# fan register map
Vendor: Texas Instruments
Peripheral module from a debugger description file (folder sc4e129bnczad).
Registers are 32-bit, read-write, no defined reset value unless marked. A register's access mark holds for its fields unless they carry their own. Offsets are as the file gives them; lines under a group give offsets from that group; [hi:lo] are bit positions; {n}, {i} and the like mark numbered series; 'fields as' and 'values as' point back to an identical list; <NAME> marks a mode.

## FAN0 — Fan Control register offsets
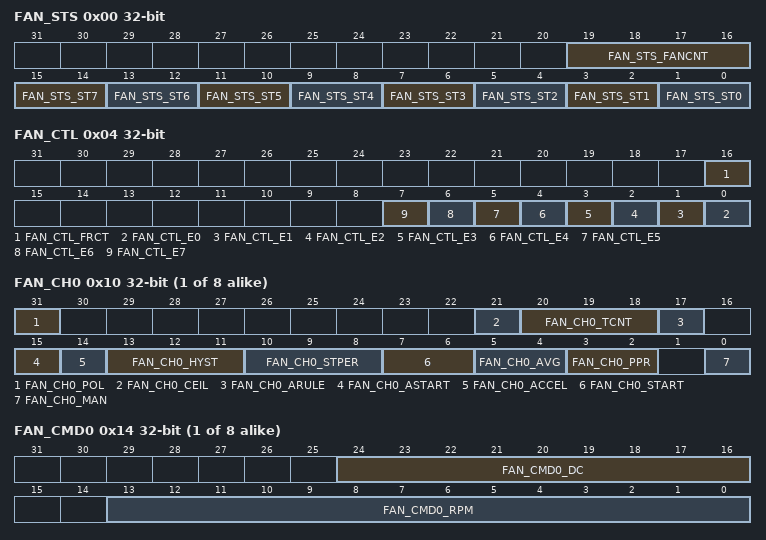
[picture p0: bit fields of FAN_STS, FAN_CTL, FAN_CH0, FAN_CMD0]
0x00 FAN_STS ro — FAN Status
  [19:16] FAN_STS_FANCNT — Fan Count
  [2n+1:2n] FAN_STS_ST{n} (n=0..7) — Fan {n} Status
    0=FAN_STS_ST{n}_STALLED (Stalled); 1=FAN_STS_ST{n}_CHANGING (Changing); 2=FAN_STS_ST{n}_LOCKED (Locked); 3=FAN_STS_ST{n}_NOATTAIN (No Attain)
0x04 FAN_CTL — FAN Control
  [16] FAN_CTL_FRCT — Fractional Output
  [n] FAN_CTL_E{n} (n=0..7) — Fan {n} Enable
{0x10+0x10*i} FAN_CH{i} (i=0..7) — FAN Channel {i} Setup
  [31] FAN_CH{i}_POL — PWM Polarity Mode
  [21] FAN_CH{i}_CEIL — Ceiling Mode
  [20:18] FAN_CH{i}_TCNT — Tachometer Count
  [17] FAN_CH{i}_ARULE — Adjustment Rule
  [15] FAN_CH{i}_ASTART — Auto Restart
  [14] FAN_CH{i}_ACCEL — Acceleration and Deceleration Rule
  [13:11] FAN_CH{i}_HYST — Hysteresis Adjustment on PID Adjust
  [10:8] FAN_CH{i}_STPER — Start Period
  [7:6] FAN_CH{i}_START — Fast Start Rule
    0=FAN_CH{i}_START_NOFAST (No fast start); 1=FAN_CH{i}_START_50DC (50% duty cycle); 2=FAN_CH{i}_START_75DC (75% duty cycle); 3=FAN_CH{i}_START_100DC (100% duty cycle)
  [5:4] FAN_CH{i}_AVG — Averaging of Tachometer
    0=No averaging; 1=Average 2 edges; 2=Average 4 edges; 3=Average 8 edges
  [3:2] FAN_CH{i}_PPR — Pulse per Revolution on Tachometer
    0=1 pulse per revolution; 1=2 pulses per revolution; 2=4 pulses per revolution; 3=8 pulses per revolution
  [0] FAN_CH{i}_MAN — Control Type
{0x14+0x10*i} FAN_CMD{i} (i=0..7) — FAN Channel {i} Command
  [24:16] FAN_CMD{i}_DC — PWM Duty Cycle
  [13:0] FAN_CMD{i}_RPM — Fan Speed (in RPM)
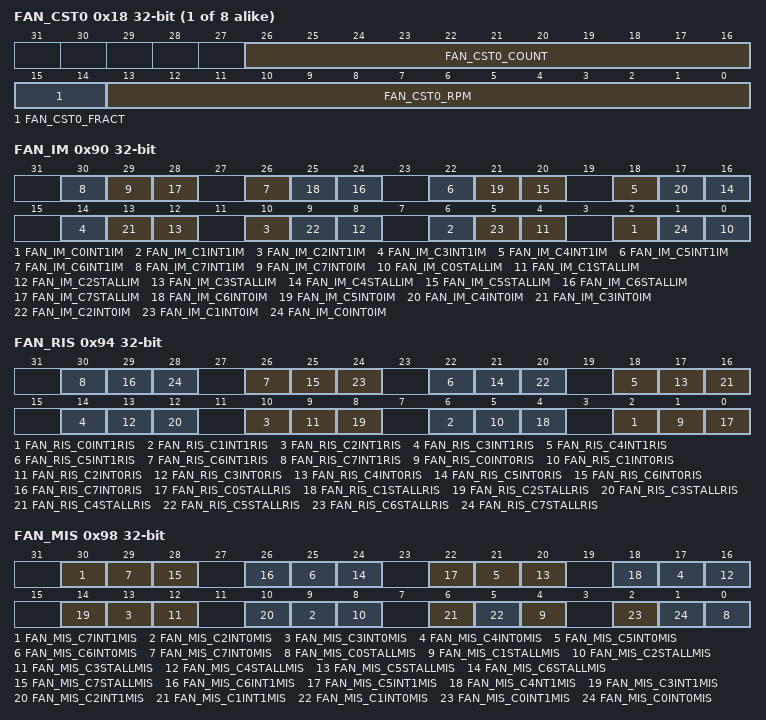
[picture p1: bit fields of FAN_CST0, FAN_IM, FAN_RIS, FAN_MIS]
{0x18+0x10*i} FAN_CST{i} ro (i=0..7) — FAN Channel {i} Status
  [26:16] FAN_CST{i}_COUNT — Last Read Tachometer Count
  [15:14] FAN_CST{i}_FRACT — Fractional Accuracy
  [13:0] FAN_CST{i}_RPM — Last Read RPM Speed Computed
0x90 FAN_IM — FAN Interrupt Mask
  [4n+2] FAN_IM_C{n}INT1IM (n=0..7) — Channel {n} (Attain) Interrupt 1 Mask
  [29] FAN_IM_C7INT0IM — Channel 7 (No Attain) Interrupt 0 Mask
  [4n] FAN_IM_C{n}STALLIM (n=0..7) — Channel {n} Stall Interrupt Mask
  [25] FAN_IM_C6INT0IM — Channel 6 (No-attain) Interrupt 0 Mask
  [21] FAN_IM_C5INT0IM — Channel 5 (No-Attain) Interrupt 0 Mask
  [17] FAN_IM_C4INT0IM — Channel 4 (No-attain) Interrupt 0 Mask
  [13] FAN_IM_C3INT0IM — Channel 3 No-Attain Interrupt 0 Mask
  [9] FAN_IM_C2INT0IM — Channel 2 (No-attain) Interrupt 0 Mask
  [5] FAN_IM_C1INT0IM — Channel 1 (No-Attain) Interrupt 0 Mask
  [1] FAN_IM_C0INT0IM — Channel 0 (No-attain) Interrupt 0 Mask
0x94 FAN_RIS ro — FAN Raw Interrupt Status
  [4n+2] FAN_RIS_C{n}INT1RIS (n=0..7) — Channel {n} Raw Interrupt 1 Status
  [4n+1] FAN_RIS_C{n}INT0RIS (n=0..7) — Channel {n} Raw Interrupt 0 Status
  [4n] FAN_RIS_C{n}STALLRIS (n=0..7) — Channel {n} Stall Raw Interrupt Status
0x98 FAN_MIS ro — FAN Masked Interrupt Status
  [30] FAN_MIS_C7INT1MIS — Channel 7 (Attain) Masked Interrupt 1 Status
  [4n+1] FAN_MIS_C{n}INT0MIS (n=2..7) — Channel {n} (No-Attain) Masked Interrupt 0 Status
  [4n] FAN_MIS_C{n}STALLMIS (n=0..7) — Channel {n} Stall Masked Interrupt Status
  [26] FAN_MIS_C6INT1MIS — Channel 6 (Attain) Masked Interrupt 1 Status
  [22] FAN_MIS_C5INT1MIS — Channel 5 (Attain) Masked Interrupt 1 Status
  [18] FAN_MIS_C4NT1MIS — Channel 4 (Attain) Masked Interrupt 1 Status
  [14] FAN_MIS_C3INT1MIS — Channel 3 (Attain) Masked Interrupt 1 Status
  [10] FAN_MIS_C2INT1MIS — Channel 2 (Attain) Masked Interrupt 1 Status
  [6] FAN_MIS_C1INT1MIS — Channel 1(Attain) Masked Interrupt 1 Status
  [5] FAN_MIS_C1INT0MIS — Channel 1 (No-Atttain) Masked Interrupt 0 Status
  [2] FAN_MIS_C0INT1MIS — Channel 0 (Attain) Masked Interrupt 1 Status
  [1] FAN_MIS_C0INT0MIS — Channel 0 (No-Attain) Masked Interrupt 0 Status
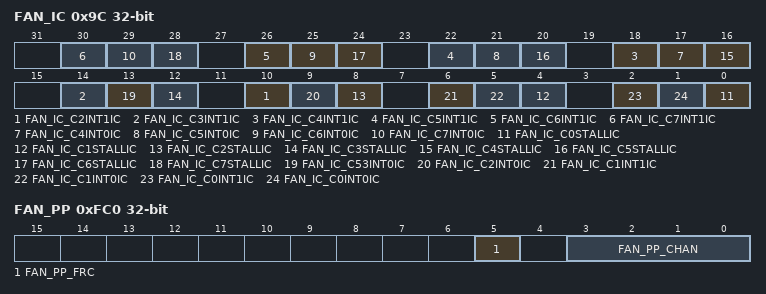
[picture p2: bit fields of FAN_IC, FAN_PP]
0x9C FAN_IC — FAN Interrupt Clear
  [4n+2] FAN_IC_C{n}INT1IC (n=2..7) — Channel {n} (Attain) Interrupt 1 Clear
  [4n+1] FAN_IC_C{n}INT0IC (n=4..7) — Channel {n} (No-Attain) Interrupt 0 Clear
  [4n] FAN_IC_C{n}STALLIC (n=0..7) — Channel {n} Stall Interrupt Clear
  [13] FAN_IC_C53INT0IC — Channel 3 (No-Attain) Interrupt 0 Clear
  [9] FAN_IC_C2INT0IC — Channel 2 (No-Attain) Interrupt 0 Clear
  [6] FAN_IC_C1INT1IC — Channel 1(Attain) Interrupt 1 Clear
  [5] FAN_IC_C1INT0IC — Channel 1 (No-Attain) Interrupt 0 Clear
  [2] FAN_IC_C0INT1IC — Channel 0 (Attain) Interrupt 1 Clear
  [1] FAN_IC_C0INT0IC — Channel 0 (No-Attain) Interrupt 0 Clear
0xFC0 FAN_PP ro — FAN Peripheral Properties
  [5] FAN_PP_FRC — Fractional Support
  [3:0] FAN_PP_CHAN — Channel Count
